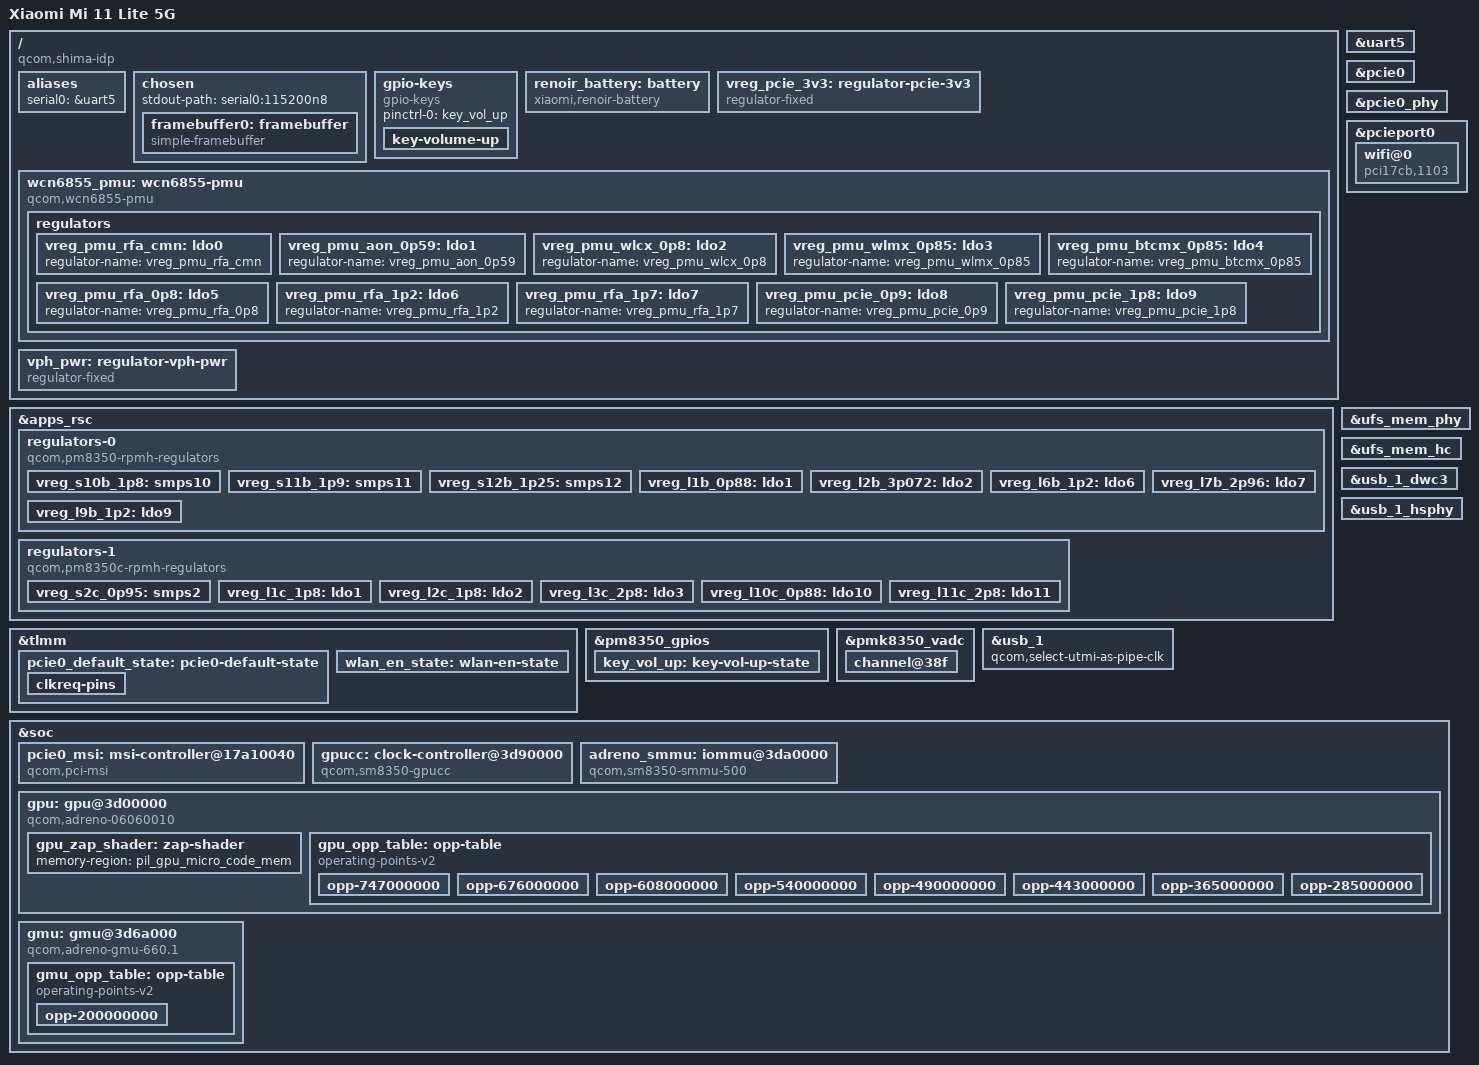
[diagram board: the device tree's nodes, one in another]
// SPDX-License-Identifier: (GPL-2.0+ OR BSD-3-Clause)
/*
 * Xiaomi Mi 11 Lite 5G (renoir / SM7350) device tree
 *
 * Copyright (c) 2026, Claude Agent <claude-agent@localhost>
 */

/dts-v1/;

#include <dt-bindings/clock/qcom,gpucc-sm8350.h>
#include <dt-bindings/gpio/gpio.h>
#include <dt-bindings/input/input.h>
#include <dt-bindings/iio/qcom,spmi-adc7-pm8350b.h>
#include <dt-bindings/interrupt-controller/arm-gic.h>
#include <dt-bindings/pinctrl/qcom,pmic-gpio.h>
#include <dt-bindings/power/qcom-rpmpd.h>
#include <dt-bindings/regulator/qcom,rpmh-regulator.h>

#include "sm7350.dtsi"
#include "pm8350.dtsi"
#include "pm8350b.dtsi"
#include "pm8350c.dtsi"
#include "pmk8350.dtsi"
#include "pmr735b.dtsi"

/ {
	model = "Xiaomi Mi 11 Lite 5G";
	compatible = "qcom,shima-idp", "qcom,shima", "qcom,idp",
		     "xiaomi,renoir", "qcom,sm7350";
	qcom,board-id = <0x22 0>;
	qcom,msm-id = <450 0x10000>;
	chassis-type = "handset";

	aliases {
		serial0 = &uart5;
	};

	chosen {
		stdout-path = "serial0:115200n8";

		#address-cells = <2>;
		#size-cells = <2>;
		ranges;

		framebuffer0: framebuffer {
			compatible = "simple-framebuffer";
			memory-region = <&splash_memory>;
			width = <1080>;
			height = <2400>;
			stride = <(1080 * 4)>;
			format = "a8r8g8b8";

			clocks = <&gcc GCC_DISP_HF_AXI_CLK>;
		};
	};

	gpio-keys {
		compatible = "gpio-keys";
		pinctrl-0 = <&key_vol_up>;
		pinctrl-names = "default";

		key-volume-up {
			label = "Volume Up";
			gpios = <&pm8350_gpios 6 GPIO_ACTIVE_LOW>;
			linux,code = <KEY_VOLUMEUP>;
		};
	};

	renoir_battery: battery {
		compatible = "xiaomi,renoir-battery";
		io-channels = <&pmk8350_vadc PM8350B_ADC7_VBAT_SNS>;
		io-channel-names = "voltage";
		status = "okay";
	};

	vreg_pcie_3v3: regulator-pcie-3v3 {
		compatible = "regulator-fixed";
		regulator-name = "vreg_pcie_3v3";
		regulator-min-microvolt = <3300000>;
		regulator-max-microvolt = <3300000>;
		regulator-always-on;
		regulator-boot-on;
	};

	wcn6855_pmu: wcn6855-pmu {
		compatible = "qcom,wcn6855-pmu";

		vddio-supply = <&vreg_s10b_1p8>;
		vddaon-supply = <&vreg_s2c_0p95>;
		vddpmu-supply = <&vreg_s2c_0p95>;
		vddpmumx-supply = <&vreg_s2c_0p95>;
		vddpmucx-supply = <&vreg_s2c_0p95>;
		vddrfa0p95-supply = <&vreg_s2c_0p95>;
		vddrfa1p3-supply = <&vreg_s12b_1p25>;
		vddrfa1p9-supply = <&vreg_s11b_1p9>;
		vddpcie1p3-supply = <&vreg_s12b_1p25>;
		vddpcie1p9-supply = <&vreg_s11b_1p9>;

		wlan-enable-gpios = <&tlmm 64 GPIO_ACTIVE_HIGH>;

		regulators {
			vreg_pmu_rfa_cmn: ldo0 {
				regulator-name = "vreg_pmu_rfa_cmn";
			};

			vreg_pmu_aon_0p59: ldo1 {
				regulator-name = "vreg_pmu_aon_0p59";
			};

			vreg_pmu_wlcx_0p8: ldo2 {
				regulator-name = "vreg_pmu_wlcx_0p8";
			};

			vreg_pmu_wlmx_0p85: ldo3 {
				regulator-name = "vreg_pmu_wlmx_0p85";
			};

			vreg_pmu_btcmx_0p85: ldo4 {
				regulator-name = "vreg_pmu_btcmx_0p85";
			};

			vreg_pmu_rfa_0p8: ldo5 {
				regulator-name = "vreg_pmu_rfa_0p8";
			};

			vreg_pmu_rfa_1p2: ldo6 {
				regulator-name = "vreg_pmu_rfa_1p2";
			};

			vreg_pmu_rfa_1p7: ldo7 {
				regulator-name = "vreg_pmu_rfa_1p7";
			};

			vreg_pmu_pcie_0p9: ldo8 {
				regulator-name = "vreg_pmu_pcie_0p9";
			};

			vreg_pmu_pcie_1p8: ldo9 {
				regulator-name = "vreg_pmu_pcie_1p8";
			};
		};
	};

	vph_pwr: regulator-vph-pwr {
		compatible = "regulator-fixed";
		regulator-name = "vph_pwr";
		regulator-min-microvolt = <3700000>;
		regulator-max-microvolt = <3700000>;
		regulator-always-on;
		regulator-boot-on;
	};
};

&apps_rsc {
	regulators-0 {
		compatible = "qcom,pm8350-rpmh-regulators";
		qcom,pmic-id = "b";

		vdd-s10-supply = <&vph_pwr>;
		vdd-s11-supply = <&vph_pwr>;
		vdd-s12-supply = <&vph_pwr>;
		vdd-l1-l4-supply = <&vph_pwr>;
		vdd-l2-l7-supply = <&vph_pwr>;
		vdd-l3-l5-supply = <&vph_pwr>;
		vdd-l6-l9-l10-supply = <&vph_pwr>;
		vdd-l8-supply = <&vph_pwr>;

		vreg_s10b_1p8: smps10 {
			regulator-name = "vreg_s10b_1p8";
			regulator-min-microvolt = <1800000>;
			regulator-max-microvolt = <1800000>;
		};

		vreg_s11b_1p9: smps11 {
			regulator-name = "vreg_s11b_1p9";
			regulator-min-microvolt = <1880000>;
			regulator-max-microvolt = <1880000>;
			regulator-initial-mode = <RPMH_REGULATOR_MODE_HPM>;
		};

		vreg_s12b_1p25: smps12 {
			regulator-name = "vreg_s12b_1p25";
			regulator-min-microvolt = <1350000>;
			regulator-max-microvolt = <1354000>;
			regulator-initial-mode = <RPMH_REGULATOR_MODE_HPM>;
		};

		vreg_l1b_0p88: ldo1 {
			regulator-name = "vreg_l1b_0p88";
			regulator-min-microvolt = <880000>;
			regulator-max-microvolt = <888000>;
			regulator-initial-mode = <RPMH_REGULATOR_MODE_HPM>;
		};

		vreg_l2b_3p072: ldo2 {
			regulator-name = "vreg_l2b_3p072";
			regulator-min-microvolt = <2700000>;
			regulator-max-microvolt = <3544000>;
			regulator-initial-mode = <RPMH_REGULATOR_MODE_HPM>;
		};

		vreg_l6b_1p2: ldo6 {
			regulator-name = "vreg_l6b_1p2";
			regulator-min-microvolt = <1140000>;
			regulator-max-microvolt = <1260000>;
			regulator-initial-mode = <RPMH_REGULATOR_MODE_HPM>;
		};

		vreg_l7b_2p96: ldo7 {
			regulator-name = "vreg_l7b_2p96";
			regulator-min-microvolt = <2400000>;
			regulator-max-microvolt = <3544000>;
			regulator-initial-mode = <RPMH_REGULATOR_MODE_HPM>;
		};

		vreg_l9b_1p2: ldo9 {
			regulator-name = "vreg_l9b_1p2";
			regulator-min-microvolt = <1080000>;
			regulator-max-microvolt = <1304000>;
			regulator-initial-mode = <RPMH_REGULATOR_MODE_HPM>;
		};
	};

	regulators-1 {
		compatible = "qcom,pm8350c-rpmh-regulators";
		qcom,pmic-id = "c";

		vdd-s2-supply = <&vph_pwr>;
		vdd-l1-l12-supply = <&vph_pwr>;
		vdd-l2-l8-supply = <&vph_pwr>;
		vdd-l3-l4-l5-l7-l13-supply = <&vph_pwr>;
		vdd-l6-l9-l11-supply = <&vph_pwr>;
		vdd-l10-supply = <&vph_pwr>;
		vdd-bob-supply = <&vph_pwr>;

		vreg_s2c_0p95: smps2 {
			regulator-name = "vreg_s2c_0p95";
			regulator-min-microvolt = <948000>;
			regulator-max-microvolt = <948000>;
			regulator-initial-mode = <RPMH_REGULATOR_MODE_HPM>;
		};

		vreg_l1c_1p8: ldo1 {
			regulator-name = "vreg_l1c_1p8";
			regulator-min-microvolt = <1620000>;
			regulator-max-microvolt = <1980000>;
			regulator-initial-mode = <RPMH_REGULATOR_MODE_HPM>;
		};

		vreg_l2c_1p8: ldo2 {
			regulator-name = "vreg_l2c_1p8";
			regulator-min-microvolt = <1800000>;
			regulator-max-microvolt = <1980000>;
			regulator-initial-mode = <RPMH_REGULATOR_MODE_HPM>;
		};

		vreg_l3c_2p8: ldo3 {
			regulator-name = "vreg_l3c_2p8";
			regulator-min-microvolt = <2800000>;
			regulator-max-microvolt = <3000000>;
			regulator-initial-mode = <RPMH_REGULATOR_MODE_HPM>;
		};

		vreg_l10c_0p88: ldo10 {
			regulator-name = "vreg_l10c_0p88";
			regulator-min-microvolt = <720000>;
			regulator-max-microvolt = <1050000>;
			regulator-initial-mode = <RPMH_REGULATOR_MODE_HPM>;
		};

		vreg_l11c_2p8: ldo11 {
			regulator-name = "vreg_l11c_2p8";
			regulator-min-microvolt = <2800000>;
			regulator-max-microvolt = <2800000>;
			regulator-initial-mode = <RPMH_REGULATOR_MODE_LPM>;
		};
	};
};

&tlmm {
	pcie0_default_state: pcie0-default-state {
		clkreq-pins {
			pins = "gpio95";
			function = "pcie0_clkreqn";
			drive-strength = <2>;
			bias-pull-up;
		};
	};

	wlan_en_state: wlan-en-state {
		pins = "gpio64";
		function = "gpio";
		drive-strength = <2>;
		bias-disable;
	};
};

&pm8350_gpios {
	key_vol_up: key-vol-up-state {
		pins = "gpio6";
		function = "normal";
		input-enable;
		bias-pull-up;
		power-source = <1>;
	};
};

&pmk8350_vadc {
	channel@38f {
		reg = <PM8350B_ADC7_VBAT_SNS>;
		label = "pm8350b_vbat_sns";
		qcom,pre-scaling = <1 3>;
	};
};

&uart5 {
	status = "okay";
};

&pcie0 {
	pinctrl-names = "default";
	pinctrl-0 = <&pcie0_default_state>;

	perst-gpios = <&tlmm 94 GPIO_ACTIVE_LOW>;
	wake-gpios = <&tlmm 96 GPIO_ACTIVE_HIGH>;

	vdda-supply = <&vreg_l10c_0p88>;
	vddpe-3v3-supply = <&vreg_pcie_3v3>;
	msi-parent = <&pcie0_msi>;

	status = "okay";
};

&pcie0_phy {
	vdda-phy-supply = <&vreg_l10c_0p88>;
	vdda-pll-supply = <&vreg_l6b_1p2>;

	status = "okay";
};

&pcieport0 {
	wifi@0 {
		compatible = "pci17cb,1103";
		reg = <0x10000 0x0 0x0 0x0 0x0>;

		vddrfacmn-supply = <&vreg_pmu_rfa_cmn>;
		vddaon-supply = <&vreg_pmu_aon_0p59>;
		vddwlcx-supply = <&vreg_pmu_wlcx_0p8>;
		vddwlmx-supply = <&vreg_pmu_wlmx_0p85>;
		vddrfa0p8-supply = <&vreg_pmu_rfa_0p8>;
		vddrfa1p2-supply = <&vreg_pmu_rfa_1p2>;
		vddrfa1p7-supply = <&vreg_pmu_rfa_1p7>;
		vddrfa1p8-supply = <&vreg_pmu_rfa_1p7>;
		vddpcie0p9-supply = <&vreg_pmu_pcie_0p9>;
		vddpcie1p8-supply = <&vreg_pmu_pcie_1p8>;
	};
};

&ufs_mem_phy {
	vdda-phy-supply = <&vreg_l10c_0p88>;
	vdda-pll-supply = <&vreg_l6b_1p2>;
	status = "okay";
};

&ufs_mem_hc {
	reset-gpios = <&tlmm 204 GPIO_ACTIVE_LOW>;

	vcc-supply = <&vreg_l7b_2p96>;
	vcc-max-microamp = <800000>;
	vccq-supply = <&vreg_l9b_1p2>;
	vccq-max-microamp = <900000>;
	vccq2-supply = <&vreg_s10b_1p8>;
	vccq2-max-microamp = <800000>;
	status = "okay";
};

&usb_1 {
	qcom,select-utmi-as-pipe-clk;
	status = "okay";
};

&usb_1_dwc3 {
	dr_mode = "otg";
	usb-role-switch;
	maximum-speed = "high-speed";
	phys = <&usb_1_hsphy>;
	phy-names = "usb2-phy";
};

&usb_1_hsphy {
	vdda-pll-supply = <&vreg_l10c_0p88>;
	vdda18-supply = <&vreg_l1c_1p8>;
	vdda33-supply = <&vreg_l2b_3p072>;
	status = "okay";
};

/*
 * GPU bring-up for the Adreno 642.  SM7350 uses the same GPU/GMU register
 * layout as SM8350's A660, but with a different chip-id (0x06060010) and a
 * lower maximum clock.  The GPUCC block and the GPU SMMU are register
 * compatible with the SM8350 variants, so use those drivers and give the
 * A642 its own catalog entry in the MSM driver.
 */
&soc {
	/*
	 * Qualcomm's PCIe MSI doorbell.  The Synopsis DWC MSI termination
	 * window is not wired up on Shima; the vendor firmware routes PCIe
	 * MSI writes to this doorbell instead, which raises GIC SPIs
	 * 768..799.
	 */
	pcie0_msi: msi-controller@17a10040 {
		compatible = "qcom,pci-msi";
		reg = <0x0 0x17a10040 0x0 0x1000>;
		msi-controller;
		#msi-cells = <0>;
		interrupt-parent = <&intc>;
		interrupts = <GIC_SPI 768 IRQ_TYPE_EDGE_RISING>,
			     <GIC_SPI 769 IRQ_TYPE_EDGE_RISING>,
			     <GIC_SPI 770 IRQ_TYPE_EDGE_RISING>,
			     <GIC_SPI 771 IRQ_TYPE_EDGE_RISING>,
			     <GIC_SPI 772 IRQ_TYPE_EDGE_RISING>,
			     <GIC_SPI 773 IRQ_TYPE_EDGE_RISING>,
			     <GIC_SPI 774 IRQ_TYPE_EDGE_RISING>,
			     <GIC_SPI 775 IRQ_TYPE_EDGE_RISING>,
			     <GIC_SPI 776 IRQ_TYPE_EDGE_RISING>,
			     <GIC_SPI 777 IRQ_TYPE_EDGE_RISING>,
			     <GIC_SPI 778 IRQ_TYPE_EDGE_RISING>,
			     <GIC_SPI 779 IRQ_TYPE_EDGE_RISING>,
			     <GIC_SPI 780 IRQ_TYPE_EDGE_RISING>,
			     <GIC_SPI 781 IRQ_TYPE_EDGE_RISING>,
			     <GIC_SPI 782 IRQ_TYPE_EDGE_RISING>,
			     <GIC_SPI 783 IRQ_TYPE_EDGE_RISING>,
			     <GIC_SPI 784 IRQ_TYPE_EDGE_RISING>,
			     <GIC_SPI 785 IRQ_TYPE_EDGE_RISING>,
			     <GIC_SPI 786 IRQ_TYPE_EDGE_RISING>,
			     <GIC_SPI 787 IRQ_TYPE_EDGE_RISING>,
			     <GIC_SPI 788 IRQ_TYPE_EDGE_RISING>,
			     <GIC_SPI 789 IRQ_TYPE_EDGE_RISING>,
			     <GIC_SPI 790 IRQ_TYPE_EDGE_RISING>,
			     <GIC_SPI 791 IRQ_TYPE_EDGE_RISING>,
			     <GIC_SPI 792 IRQ_TYPE_EDGE_RISING>,
			     <GIC_SPI 793 IRQ_TYPE_EDGE_RISING>,
			     <GIC_SPI 794 IRQ_TYPE_EDGE_RISING>,
			     <GIC_SPI 795 IRQ_TYPE_EDGE_RISING>,
			     <GIC_SPI 796 IRQ_TYPE_EDGE_RISING>,
			     <GIC_SPI 797 IRQ_TYPE_EDGE_RISING>,
			     <GIC_SPI 798 IRQ_TYPE_EDGE_RISING>,
			     <GIC_SPI 799 IRQ_TYPE_EDGE_RISING>;
	};

	gpucc: clock-controller@3d90000 {
		compatible = "qcom,sm8350-gpucc";
		reg = <0x0 0x03d90000 0x0 0x9000>;
		clocks = <&rpmhcc RPMH_CXO_CLK>,
			 <&gcc GCC_GPU_GPLL0_CLK_SRC>,
			 <&gcc GCC_GPU_GPLL0_DIV_CLK_SRC>;
		clock-names = "bi_tcxo",
			      "gcc_gpu_gpll0_clk_src",
			      "gcc_gpu_gpll0_div_clk_src";
		#clock-cells = <1>;
		#reset-cells = <1>;
		#power-domain-cells = <1>;
	};

	adreno_smmu: iommu@3da0000 {
		compatible = "qcom,sm8350-smmu-500", "qcom,adreno-smmu",
			     "qcom,smmu-500", "arm,mmu-500";
		reg = <0x0 0x03da0000 0x0 0x20000>;
		#iommu-cells = <2>;
		#global-interrupts = <2>;
		interrupts = <GIC_SPI 673 IRQ_TYPE_LEVEL_HIGH>,
			     <GIC_SPI 675 IRQ_TYPE_LEVEL_HIGH>,
			     <GIC_SPI 678 IRQ_TYPE_LEVEL_HIGH>,
			     <GIC_SPI 679 IRQ_TYPE_LEVEL_HIGH>,
			     <GIC_SPI 680 IRQ_TYPE_LEVEL_HIGH>,
			     <GIC_SPI 681 IRQ_TYPE_LEVEL_HIGH>,
			     <GIC_SPI 682 IRQ_TYPE_LEVEL_HIGH>,
			     <GIC_SPI 683 IRQ_TYPE_LEVEL_HIGH>,
			     <GIC_SPI 684 IRQ_TYPE_LEVEL_HIGH>,
			     <GIC_SPI 685 IRQ_TYPE_LEVEL_HIGH>,
			     <GIC_SPI 686 IRQ_TYPE_LEVEL_HIGH>,
			     <GIC_SPI 687 IRQ_TYPE_LEVEL_HIGH>;
		clocks = <&gcc GCC_GPU_MEMNOC_GFX_CLK>,
			 <&gcc GCC_GPU_SNOC_DVM_GFX_CLK>,
			 <&gpucc GPU_CC_AHB_CLK>,
			 <&gpucc GPU_CC_HLOS1_VOTE_GPU_SMMU_CLK>,
			 <&gpucc GPU_CC_CX_GMU_CLK>,
			 <&gpucc GPU_CC_HUB_CX_INT_CLK>,
			 <&gpucc GPU_CC_HUB_AON_CLK>;
		clock-names = "bus", "iface", "ahb",
			      "hlos1_vote_gpu_smmu", "cx_gmu",
			      "hub_cx_int", "hub_aon";
		power-domains = <&gpucc GPU_CX_GDSC>;
		dma-coherent;
	};

	gpu: gpu@3d00000 {
		compatible = "qcom,adreno-06060010", "qcom,adreno";
		reg = <0x0 0x03d00000 0x0 0x40000>,
		      <0x0 0x03d9e000 0x0 0x1000>,
		      <0x0 0x03d61000 0x0 0x800>;
		reg-names = "kgsl_3d0_reg_memory", "cx_mem", "cx_dbgc";
		interrupts = <GIC_SPI 300 IRQ_TYPE_LEVEL_HIGH>;
		iommus = <&adreno_smmu 0 0x400>,
			 <&adreno_smmu 1 0x400>;
		operating-points-v2 = <&gpu_opp_table>;
		qcom,gmu = <&gmu>;
		#cooling-cells = <2>;
		status = "okay";

		gpu_zap_shader: zap-shader {
			memory-region = <&pil_gpu_micro_code_mem>;
		};

		gpu_opp_table: opp-table {
			compatible = "operating-points-v2";

			opp-747000000 {
				opp-hz = /bits/ 64 <747000000>;
				opp-level = <RPMH_REGULATOR_LEVEL_NOM_L1>;
			};

			opp-676000000 {
				opp-hz = /bits/ 64 <676000000>;
				opp-level = <RPMH_REGULATOR_LEVEL_NOM>;
			};

			opp-608000000 {
				opp-hz = /bits/ 64 <608000000>;
				opp-level = <RPMH_REGULATOR_LEVEL_SVS_L2>;
			};

			opp-540000000 {
				opp-hz = /bits/ 64 <540000000>;
				opp-level = <RPMH_REGULATOR_LEVEL_SVS_L1>;
			};

			opp-490000000 {
				opp-hz = /bits/ 64 <490000000>;
				opp-level = <RPMH_REGULATOR_LEVEL_SVS_L0>;
			};

			opp-443000000 {
				opp-hz = /bits/ 64 <443000000>;
				opp-level = <RPMH_REGULATOR_LEVEL_SVS>;
			};

			opp-365000000 {
				opp-hz = /bits/ 64 <365000000>;
				opp-level = <RPMH_REGULATOR_LEVEL_LOW_SVS_L1>;
			};

			opp-285000000 {
				opp-hz = /bits/ 64 <285000000>;
				opp-level = <RPMH_REGULATOR_LEVEL_LOW_SVS>;
			};
		};
	};

	gmu: gmu@3d6a000 {
		compatible = "qcom,adreno-gmu-660.1", "qcom,adreno-gmu";
		reg = <0x0 0x03d6a000 0x0 0x34000>,
		      <0x0 0x03de0000 0x0 0x10000>,
		      <0x0 0x0b290000 0x0 0x10000>;
		reg-names = "gmu", "rscc", "gmu_pdc";
		interrupts = <GIC_SPI 304 IRQ_TYPE_LEVEL_HIGH>,
			     <GIC_SPI 305 IRQ_TYPE_LEVEL_HIGH>;
		interrupt-names = "hfi", "gmu";
		clocks = <&gpucc GPU_CC_CX_GMU_CLK>,
			 <&gpucc GPU_CC_CXO_CLK>,
			 <&gcc GCC_DDRSS_GPU_AXI_CLK>,
			 <&gcc GCC_GPU_MEMNOC_GFX_CLK>,
			 <&gpucc GPU_CC_AHB_CLK>,
			 <&gpucc GPU_CC_HUB_CX_INT_CLK>,
			 <&gpucc GPU_CC_HLOS1_VOTE_GPU_SMMU_CLK>;
		clock-names = "gmu", "cxo", "axi", "memnoc", "ahb",
			      "hub", "smmu_vote";
		power-domains = <&gpucc GPU_CX_GDSC>,
				<&gpucc GPU_GX_GDSC>;
		power-domain-names = "cx", "gx";
		iommus = <&adreno_smmu 5 0x400>;
		operating-points-v2 = <&gmu_opp_table>;

		gmu_opp_table: opp-table {
			compatible = "operating-points-v2";

			opp-200000000 {
				opp-hz = /bits/ 64 <200000000>;
				opp-level = <RPMH_REGULATOR_LEVEL_MIN_SVS>;
			};
		};
	};
};
